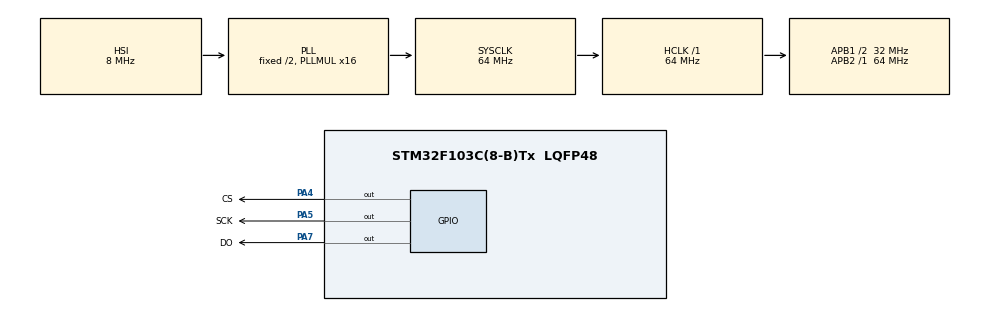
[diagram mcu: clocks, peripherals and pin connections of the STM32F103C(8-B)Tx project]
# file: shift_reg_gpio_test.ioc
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Mcu.Family=STM32F1
Mcu.Name=STM32F103C(8-B)Tx
Mcu.Package=LQFP48
NVIC.PriorityGroup=NVIC_PRIORITYGROUP_4
PA4.GPIO_Label=CS
PA4.Signal=GPIO_Output
PA5.GPIO_Label=SCK
PA5.Signal=GPIO_Output
PA7.GPIO_Label=DO
PA7.Signal=GPIO_Output
ProjectManager.HeapSize=0x200
ProjectManager.StackSize=0x400
ProjectManager.TargetToolchain=STM32CubeIDE
RCC.AHBFreq_Value=64000000
RCC.APB1CLKDivider=RCC_HCLK_DIV2
RCC.APB1Freq_Value=32000000
RCC.APB1TimFreq_Value=64000000
RCC.APB2Freq_Value=64000000
RCC.APB2TimFreq_Value=64000000
RCC.HCLKFreq_Value=64000000
RCC.PLLMUL=RCC_PLL_MUL16
RCC.SYSCLKFreq_VALUE=64000000
RCC.SYSCLKSource=RCC_SYSCLKSOURCE_PLLCLK
RCC.USBFreq_Value=64000000
board=custom

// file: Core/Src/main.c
/* USER CODE BEGIN Header */
/**
  ******************************************************************************
  * @file           : main.c
  * @brief          : Main program body
  ******************************************************************************
  * @attention
  *
  * Copyright (c) 2023 STMicroelectronics.
  * All rights reserved.
  *
  * This software is licensed under terms that can be found in the LICENSE file
  * in the root directory of this software component.
  * If no LICENSE file comes with this software, it is provided AS-IS.
  *
  ******************************************************************************
  */
/* USER CODE END Header */
#include "main.h"
#include "gpio.h"

void SystemClock_Config(void);

/* USER CODE BEGIN 0 */
// Toggle chip select
int ShiftRegister_Strob()
{
	HAL_GPIO_WritePin(CS_GPIO_Port, CS_Pin, GPIO_PIN_SET);
	HAL_GPIO_WritePin(CS_GPIO_Port, CS_Pin, GPIO_PIN_RESET);
	return 0;
}

int ShiftRegister_Set (uint8_t val)
{
	for (int i = 0; i < 8; i++)
	{
		HAL_GPIO_WritePin(SCK_GPIO_Port, SCK_Pin, GPIO_PIN_RESET);
		uint8_t out = (val & 0x80) >> 7;
		if (out)
		{
			HAL_GPIO_WritePin(DO_GPIO_Port, DO_Pin, GPIO_PIN_SET);
		}
		else
		{
			HAL_GPIO_WritePin(DO_GPIO_Port, DO_Pin, GPIO_PIN_RESET);
		}
		HAL_Delay(2);
		val <<= 1;
		HAL_GPIO_WritePin(SCK_GPIO_Port, SCK_Pin, GPIO_PIN_SET);
		HAL_Delay(2);
	}
	return 0;
}

int ShifRegister_Clear()
{
	HAL_GPIO_WritePin(DO_GPIO_Port, DO_Pin, GPIO_PIN_SET);
	for (int i = 0; i < 8; i++)
	{
		HAL_GPIO_WritePin(SCK_GPIO_Port, SCK_Pin, GPIO_PIN_RESET);
		HAL_Delay(2);
		HAL_GPIO_WritePin(SCK_GPIO_Port, SCK_Pin, GPIO_PIN_SET);
		HAL_Delay(2);
	}
	ShiftRegister_Strob();
	HAL_Delay(2);
	HAL_GPIO_WritePin(DO_GPIO_Port, DO_Pin, GPIO_PIN_RESET);
	HAL_Delay(2);
	return 0;
}
/* USER CODE END 0 */

int main(void)
{

  /* MCU Configuration--------------------------------------------------------*/

  /* Reset of all peripherals, Initializes the Flash interface and the Systick. */
  HAL_Init();

  /* Configure the system clock */
  SystemClock_Config();

  /* Initialize all configured peripherals */
  MX_GPIO_Init();
  /* USER CODE BEGIN 2 */
//  ShifRegister_Clear();
  ShifRegister_Clear();
//  ShiftRegister_Set (~0x04);
//  ShiftRegister_Strob();
  /* USER CODE END 2 */

  /* Infinite loop */
  /* USER CODE BEGIN WHILE */
  //uint8_t numbers[8] = {~0x01, ~0x02, ~0x04, ~0x08, ~0x10, ~0x20, ~0x40, ~0x80}; // 1, 2, 3, 4, 5
  uint8_t numbers[16] = {~0x3F, ~0x06, ~0x5B, ~0x4F, ~0x66, ~0x6D, ~0x7D, ~0x07, ~0x7F, ~0x6F, ~0x77, ~0x7C, ~0x39, ~0x5E, ~0x79, ~0x71}; // 0-F
  while (1)
  {
    /* USER CODE END WHILE */
      for(int i=0; i<sizeof(numbers); i++)

       {
    	  	  ShiftRegister_Set (numbers[i]);
    	  	  ShiftRegister_Strob();
               HAL_Delay(1000);
       }
  }
}

void SystemClock_Config(void)
{
  RCC_OscInitTypeDef RCC_OscInitStruct = {0};
  RCC_ClkInitTypeDef RCC_ClkInitStruct = {0};

  /** Initializes the RCC Oscillators according to the specified parameters
  * in the RCC_OscInitTypeDef structure.
  */
  RCC_OscInitStruct.OscillatorType = RCC_OSCILLATORTYPE_HSI;
  RCC_OscInitStruct.HSIState = RCC_HSI_ON;
  RCC_OscInitStruct.HSICalibrationValue = RCC_HSICALIBRATION_DEFAULT;
  RCC_OscInitStruct.PLL.PLLState = RCC_PLL_ON;
  RCC_OscInitStruct.PLL.PLLSource = RCC_PLLSOURCE_HSI_DIV2;
  RCC_OscInitStruct.PLL.PLLMUL = RCC_PLL_MUL16;
  if (HAL_RCC_OscConfig(&RCC_OscInitStruct) != HAL_OK)
  {
    Error_Handler();
  }

  /** Initializes the CPU, AHB and APB buses clocks
  */
  RCC_ClkInitStruct.ClockType = RCC_CLOCKTYPE_HCLK|RCC_CLOCKTYPE_SYSCLK
                              |RCC_CLOCKTYPE_PCLK1|RCC_CLOCKTYPE_PCLK2;
  RCC_ClkInitStruct.SYSCLKSource = RCC_SYSCLKSOURCE_PLLCLK;
  RCC_ClkInitStruct.AHBCLKDivider = RCC_SYSCLK_DIV1;
  RCC_ClkInitStruct.APB1CLKDivider = RCC_HCLK_DIV2;
  RCC_ClkInitStruct.APB2CLKDivider = RCC_HCLK_DIV1;

  if (HAL_RCC_ClockConfig(&RCC_ClkInitStruct, FLASH_LATENCY_2) != HAL_OK)
  {
    Error_Handler();
  }
}

void Error_Handler(void)
{
  __disable_irq();
  while (1)
  {
  }
}
